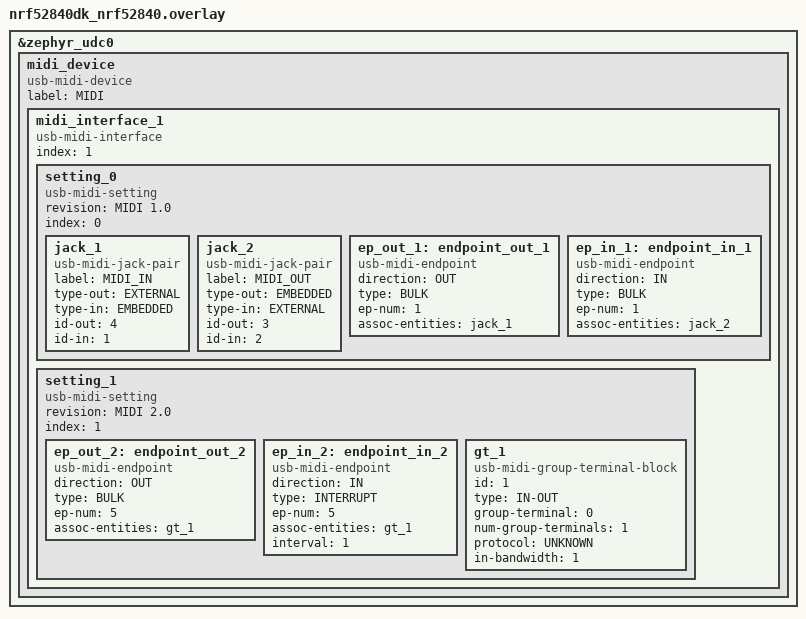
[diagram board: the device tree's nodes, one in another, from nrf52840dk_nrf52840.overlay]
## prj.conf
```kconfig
# Enable DK LED and Buttons library
CONFIG_DK_LIBRARY=y
CONFIG_GPIO=y

# Config logger
CONFIG_LOG=y
CONFIG_USE_SEGGER_RTT=y
CONFIG_LOG_BACKEND_RTT=y
CONFIG_LOG_BACKEND_UART=n


CONFIG_USB_DRIVER_LOG_LEVEL_DBG=y
CONFIG_USB_DEVICE_LOG_LEVEL_DBG=y

CONFIG_ASSERT=y

#USB related configs
# CONFIG_USB_DEVICE_DRIVER=y
CONFIG_USB_DEVICE_STACK=y
CONFIG_USB_DEVICE_PRODUCT="Zephyr USB MIDI sample"

#net buf options
CONFIG_NET_BUF=y

CONFIG_USB_DEVICE_MIDI=y

CONFIG_HEAP_MEM_POOL_SIZE=512

CONFIG_MIDI=y
```

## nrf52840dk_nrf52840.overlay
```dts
/*
 * Copyright (c) 2019 Nordic Semiconductor ASA
 *
 * SPDX-License-Identifier: Apache-2.0
 */

&zephyr_udc0 {
	midi_device {
		compatible = "usb-midi-device";
		label = "MIDI";

		midi_interface_1 {
			compatible = "usb-midi-interface";
			index = <1>;
			setting_0 {
				compatible = "usb-midi-setting";
				revision = "MIDI 1.0";
				index = <0>;

				jack_1: jack_1 {
					label = "MIDI_IN";
					compatible = "usb-midi-jack-pair";
					type-out = "EXTERNAL";
					type-in = "EMBEDDED";
					id-out = <4>;
					id-in = <1>;
				};

				jack_2: jack_2 {
					label = "MIDI_OUT";
					compatible = "usb-midi-jack-pair";
					type-out = "EMBEDDED";
					type-in = "EXTERNAL";
					id-out = <3>;
					id-in = <2>;
				};
		
				ep_out_1: endpoint_out_1 {
					compatible = "usb-midi-endpoint";
					direction = "OUT";
					type = "BULK";
					ep-num = <1>;
					assoc-entities = <&jack_1>;
					
				};
		
				ep_in_1: endpoint_in_1 {
					compatible = "usb-midi-endpoint";
					direction = "IN";
					type = "BULK";
					ep-num = <1>;
					assoc-entities = <&jack_2>;
				};
			};
			
			setting_1 {
				compatible = "usb-midi-setting";
				revision = "MIDI 2.0";
				index = <1>;

				ep_out_2: endpoint_out_2 {
					compatible = "usb-midi-endpoint";
					direction = "OUT";
					type = "BULK";
					ep-num = <5>;
					assoc-entities = <&gt_1>;
					
				};
		
				ep_in_2: endpoint_in_2 {
					compatible = "usb-midi-endpoint";
					direction = "IN";
					type = "INTERRUPT";
					ep-num = <5>;
					assoc-entities = <&gt_1>;
					interval = <1>;
				};
		
				gt_1: gt_1 {
					compatible = "usb-midi-group-terminal-block";
					id = <1>;
					type = "IN-OUT";
					group-terminal = <0>;
					num-group-terminals = <1>;
					protocol = "UNKNOWN";
					in-bandwidth = <1>;
				};
			};
		};
	};
};

// &midi {
// 	midi_device{
// 		compatible:
// 	}
// }
```

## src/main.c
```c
#include <zephyr/types.h>
#include <zephyr/device.h>
#include <soc.h>

#include <dk_buttons_and_leds.h>
#include <zephyr/usb/usb_device.h>
#include <usb/class/usb_midi.h>
#include <midi/midi.h>

#include <zephyr/logging/log.h>

#define LOG_MODULE_NAME USB_midi
LOG_MODULE_REGISTER(LOG_MODULE_NAME);

#define RUN_STATUS_LED DK_LED1
#define RUN_LED_BLINK_INTERVAL 1000

const struct device *midi_out_dev;

static int midi_sent(const struct device *dev,
			  midi_msg_t *msg,
			  void *user_data)
{

	if (!msg) {
		/* This should never happen */
		return -EINVAL;
	}

	LOG_INF("MIDI sent!");

	midi_msg_unref(msg);

	return 0;
}

static int midi_received(const struct device *dev,
			  midi_msg_t *msg,
			  void *user_data)
{

	if (!msg) {
		/* This should never happen */
		return -EINVAL;
	}
	LOG_HEXDUMP_INF(msg->data, msg->len, "main:");

	midi_send(midi_out_dev, msg);
	return 0;
}

static const struct usb_midi_ops ops = {
};

void main(void)
{
	int blink_status = 0;
	int err;
	const struct device *usb_midi_dev;
	const struct device *midi_in_dev;

	// LOG_INF("Entered %s", __func__);
	usb_midi_dev = device_get_binding("MIDI");

	if (!usb_midi_dev) {
		LOG_ERR("Can not get USB MIDI Device");
		return;
	}

	midi_in_dev = device_get_binding("MIDI_IN");
	if (!midi_in_dev) {
		LOG_ERR("Can not get MIDI IN PORT Device");
		return;
	}

	err = midi_callback_set(midi_in_dev, midi_received, NULL);
	if (err != 0) {
		LOG_ERR("Can not set MIDI IN callbacks");
	}

	midi_out_dev = device_get_binding("MIDI_OUT");
	if (!midi_out_dev) {
		LOG_ERR("Can not get MIDI OUT PORT Device");
		return;
	}

	err = midi_callback_set(midi_out_dev, midi_sent, NULL);
	if (err != 0) {
		LOG_ERR("Can not set MIDI IN callbacks");
	}

	// LOG_INF("Found USB MIDI Device");

	usb_midi_register(usb_midi_dev, &ops);
	
	err = usb_enable(NULL);
	if (err != 0) {
		LOG_ERR("Failed to enable USB");
		return;
	}

	// LOG_INF("USB enabled");

	err = dk_leds_init();
	if (err) {
		LOG_ERR("Cannot init LEDs (err: %d)", err);
	}

	test_func();

	for (;;) {
		dk_set_led(RUN_STATUS_LED, (++blink_status) % 2);
		k_sleep(K_MSEC(RUN_LED_BLINK_INTERVAL));
	}
}
```
